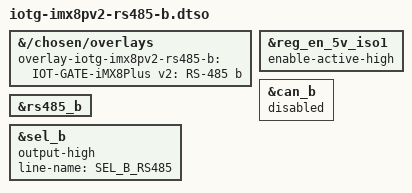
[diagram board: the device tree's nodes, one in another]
#include "overlay.h"

&{/chosen/overlays} {
	overlay-iotg-imx8pv2-rs485-b = "IOT-GATE-iMX8Plus v2: RS-485 b";
};

/* Enable ISO1_5V */
&reg_en_5v_iso1 {
	enable-active-high;
};

/* Disable CAN B interface */
&can_b {
	status = "disabled";
};

/* Enable RS485 B interface */
&rs485_b {
	status = "okay";
};

/* Select RS485 signals on the MUX-A */
&sel_b {
	output-high;
	line-name = "SEL_B_RS485";
	status = "okay";
};
